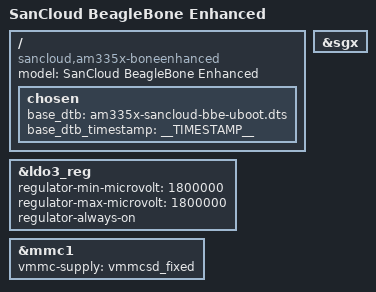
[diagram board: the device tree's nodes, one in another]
// SPDX-License-Identifier: GPL-2.0-only
/*
 * Copyright (C) 2012 Texas Instruments Incorporated - https://www.ti.com/
 */
/dts-v1/;

#include "am33xx.dtsi"
#include "am335x-sancloud-bbe-common.dtsi"

/ {
	model = "SanCloud BeagleBone Enhanced";
	compatible = "sancloud,am335x-boneenhanced", "ti,am335x-bone-black", "ti,am335x-bone", "ti,am33xx";

	chosen {
		base_dtb = "am335x-sancloud-bbe-uboot.dts";
		base_dtb_timestamp = __TIMESTAMP__;
	};
};

&sgx {
	status = "okay";
};

&ldo3_reg {
	regulator-min-microvolt = <1800000>;
	regulator-max-microvolt = <1800000>;
	regulator-always-on;
};

&mmc1 {
	vmmc-supply = <&vmmcsd_fixed>;
};
